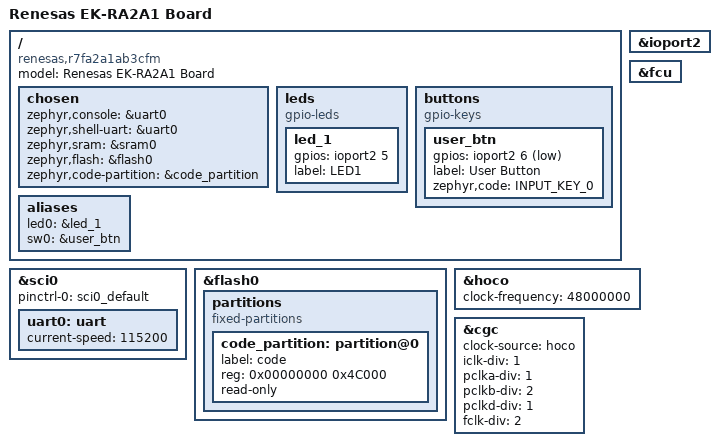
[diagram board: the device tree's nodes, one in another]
/*
 * Copyright (c) 2024 TOKITA Hiroshi <tokita.hiroshi@gmail.com>
 *
 * SPDX-License-Identifier: Apache-2.0
 */

/dts-v1/;

#include <zephyr/dt-bindings/gpio/gpio.h>

#include <zephyr/dt-bindings/input/input-event-codes.h>
#include <renesas/ra/r7fa2a1ab3cfm.dtsi>

#include "ek_ra2a1-pinctrl.dtsi"

/ {
	model = "Renesas EK-RA2A1 Board";
	compatible = "renesas,r7fa2a1ab3cfm";

	chosen {
		zephyr,console = &uart0;
		zephyr,shell-uart = &uart0;
		zephyr,sram = &sram0;
		zephyr,flash = &flash0;
		zephyr,code-partition = &code_partition;
	};

	leds {
		compatible = "gpio-leds";
		led_1: led_1 {
			gpios = <&ioport2 5 GPIO_ACTIVE_HIGH>;
			label = "LED1";
		};
	};

	buttons {
		compatible = "gpio-keys";

		user_btn: user_btn {
			gpios = <&ioport2 6 GPIO_ACTIVE_LOW>;
			label = "User Button";
			zephyr,code = <INPUT_KEY_0>;
		};
	};

	aliases {
		led0 = &led_1;
		sw0 = &user_btn;
	};
};

&sci0 {
	status = "okay";
	pinctrl-0 = <&sci0_default>;
	pinctrl-names = "default";
	uart0: uart {
		current-speed = <115200>;
		status = "okay";
	};
};

&ioport2 {
	status = "okay";
};

&flash0 {
	partitions {
		compatible = "fixed-partitions";
		#address-cells = <1>;
		#size-cells = <1>;

		code_partition: partition@0 {
			label = "code";
			reg = <0x00000000 0x4C000>;
			read-only;
		};
	};
};

&fcu {
	status = "okay";
};

&hoco {
	status = "okay";
	clock-frequency = <48000000>;
};

&cgc {
	clock-source = <&hoco>;
	iclk-div = <1>;
	pclka-div = <1>;
	pclkb-div = <2>;
	pclkd-div = <1>;
	fclk-div = <2>;
};
